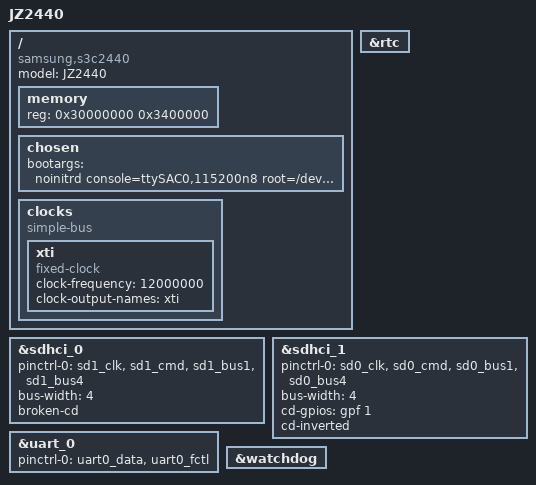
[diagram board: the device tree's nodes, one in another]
/*
 * SAMSUNG SMDK2416 board device tree source
 *
 * Copyright (c) 2013 Heiko Stuebner <heiko@sntech.de>
 *
 * This program is free software; you can redistribute it and/or modify
 * it under the terms of the GNU General Public License version 2 as
 * published by the Free Software Foundation.
 */

/dts-v1/;
#include "s3c2440.dtsi"

/ {
	model = "JZ2440";
	compatible = "samsung,s3c2440";

	memory {
		reg =  <0x30000000 0x3400000>;
	};
    
    chosen {
         bootargs = "noinitrd console=ttySAC0,115200n8 root=/dev/mtdblock3 init=/linuxrc rootfstype=jffs2 ignore_loglevel earlyprintk";
    };

	clocks {
		compatible = "simple-bus";
		#address-cells = <1>;
		#size-cells = <1>;

		xti: xti {
			compatible = "fixed-clock";
			clock-frequency = <12000000>;
			clock-output-names = "xti";
			#clock-cells = <0>;
		};
	};
};

&rtc {
	status = "okay";
};

&sdhci_0 {
	pinctrl-names = "default";
	pinctrl-0 = <&sd1_clk>, <&sd1_cmd>,
			<&sd1_bus1>, <&sd1_bus4>;
	bus-width = <4>;
	broken-cd;
	status = "okay";
};

&sdhci_1 {
	pinctrl-names = "default";
	pinctrl-0 = <&sd0_clk>, <&sd0_cmd>,
			<&sd0_bus1>, <&sd0_bus4>;
	bus-width = <4>;
	cd-gpios = <&gpf 1 0>;
	cd-inverted;
	status = "okay";
};

&uart_0 {
	status = "okay";
	pinctrl-names = "default";
	pinctrl-0 = <&uart0_data>, <&uart0_fctl>;
};

/*
&uart_1 {
	status = "okay";
	pinctrl-names = "default";
	pinctrl-0 = <&uart1_data>, <&uart1_fctl>;
};

&uart_2 {
	status = "okay";
	pinctrl-names = "default";
	pinctrl-0 = <&uart2_data>;
};

&uart_3 {
	status = "okay";
	pinctrl-names = "default";
	pinctrl-0 = <&uart3_data>;
};
*/

&watchdog {
	status = "okay";
};
